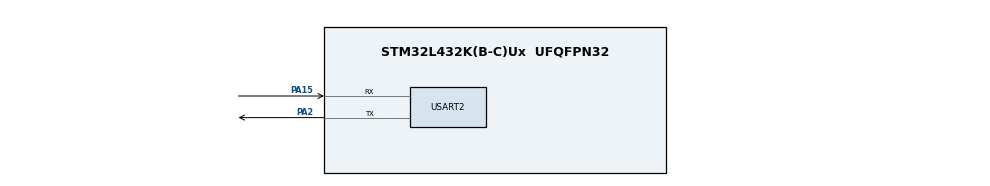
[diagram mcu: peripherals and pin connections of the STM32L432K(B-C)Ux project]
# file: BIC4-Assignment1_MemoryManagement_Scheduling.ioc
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FREERTOS.Tasks01=fibonacciTask,24,128,startFibonacciTask,Default,NULL,Dynamic,NULL,NULL;outputTask,24,128,startOutputTask,Default,NULL,Dynamic,NULL,NULL;devideTask,24,128,startDevideTask,Default,NULL,Dynamic,NULL,NULL;printBinaryTask,24,128,startPrintBinaryTask,Default,NULL,Dynamic,NULL,NULL
FREERTOS.configUSE_NEWLIB_REENTRANT=1
FREERTOS.configUSE_PREEMPTION=1
Mcu.Family=STM32L4
Mcu.Name=STM32L432K(B-C)Ux
Mcu.Package=UFQFPN32
NVIC.PriorityGroup=NVIC_PRIORITYGROUP_4
NVIC.TIM6_DAC_IRQn=true\:15\:0\:false\:false\:true\:false\:false\:true
NVIC.TimeBase=TIM6_DAC_IRQn
NVIC.TimeBaseIP=TIM6
NVIC.USART2_IRQn=true\:5\:0\:false\:false\:true\:true\:true\:true
PA13\ (JTMS-SWDIO).Mode=Serial_Wire
PA13\ (JTMS-SWDIO).Signal=SYS_JTMS-SWDIO
PA14\ (JTCK-SWCLK).Mode=Serial_Wire
PA14\ (JTCK-SWCLK).Signal=SYS_JTCK-SWCLK
PA15\ (JTDI).Mode=Asynchronous
PA15\ (JTDI).Signal=USART2_RX
PA2.Mode=Asynchronous
PA2.Signal=USART2_TX
ProjectManager.HeapSize=0x200
ProjectManager.StackSize=0x400
ProjectManager.TargetToolchain=STM32CubeIDE
RCC.HSE_VALUE=8000000
RCC.HSI48_VALUE=48000000
RCC.HSI_VALUE=16000000
RCC.LSE_VALUE=32768
RCC.MSI_VALUE=4000000
RCC.VCOOutputFreq_Value=32000000
USART2.VirtualMode-Asynchronous=VM_ASYNC
VP_FREERTOS_VS_CMSIS_V2.Mode=CMSIS_V2
VP_SYS_VS_tim6.Mode=TIM6
board=custom

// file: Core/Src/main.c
/* USER CODE BEGIN Header */
/**
  ******************************************************************************
  * @file           : main.c
  * @brief          : Main program body
  ******************************************************************************
  * @attention
  *
  * <h2><center>&copy; Copyright (c) 2022 STMicroelectronics.
  * All rights reserved.</center></h2>
  *
  * This software component is licensed by ST under BSD 3-Clause license,
  * the "License"; You may not use this file except in compliance with the
  * License. You may obtain a copy of the License at:
  *                        opensource.org/licenses/BSD-3-Clause
  *
  ******************************************************************************
  */
/* USER CODE END Header */
#include "main.h"
#include "cmsis_os.h"

/* USER CODE BEGIN Includes */
#include <stdlib.h>
#include <stdio.h>
/* USER CODE END Includes */

UART_HandleTypeDef huart2;

/* Definitions for fibonacciTask */
osThreadId_t fibonacciTaskHandle;
const osThreadAttr_t fibonacciTask_attributes = {
  .name = "fibonacciTask",
  .stack_size = 128 * 4,
  .priority = (osPriority_t) osPriorityNormal,
};
/* Definitions for outputTask */
osThreadId_t outputTaskHandle;
const osThreadAttr_t outputTask_attributes = {
  .name = "outputTask",
  .stack_size = 128 * 4,
  .priority = (osPriority_t) osPriorityNormal,
};
/* Definitions for devideTask */
osThreadId_t devideTaskHandle;
const osThreadAttr_t devideTask_attributes = {
  .name = "devideTask",
  .stack_size = 128 * 4,
  .priority = (osPriority_t) osPriorityNormal,
};
/* Definitions for printBinaryTask */
osThreadId_t printBinaryTaskHandle;
const osThreadAttr_t printBinaryTask_attributes = {
  .name = "printBinaryTask",
  .stack_size = 128 * 4,
  .priority = (osPriority_t) osPriorityNormal,
};

void SystemClock_Config(void);
static void MX_GPIO_Init(void);
static void MX_USART2_UART_Init(void);
void startFibonacciTask(void *argument);
void startOutputTask(void *argument);
void startDevideTask(void *argument);
void startPrintBinaryTask(void *argument);

/* USER CODE BEGIN 0 */

/**
  * @brief Fibonacci-Zahl berechnen
  * @param Index der Fibonacci-Folge
  * @retval Fibonacci-Zahl des Indexes
  */
int fibonacci(int zahl) {

	/* Die Fibonacci-Zahl von null ist null */
    if (zahl == 0) {
        return 0;
    }

    /* Die Fibonacci-Zahl von eins ist eins */
    if (zahl == 1) {
        return 1;
    }

    /* Ansonsten wird die Summe der zwei vorherigen Fibonacci-Zahlen zurückgegeben. */
    return fibonacci(zahl - 1) + fibonacci(zahl - 2);
}

/**
  * @brief Rest einer Zahl berechnen
  * @param Dividend
  * @param Devisor
  * @retval Ergebnis
  */
int divide(int x, int y) {

   if(x >= y)
	   return (1 + divide(x - y, y));
   if(x)
	   // printf("Zahl nicht teilbar -> Rest: %d -> ", x);
   return 0;
}

/**
  * @brief Dezimalzahl in Binärdarstellung darstellen
  * @param Dezimalzahl
  * @retval none
  */
void printBinary(long x) {
    if (x<2)
    {
    	// printf("%d",x);
    }
    else
    {
    	printBinary(x/2);
    	// printf("%d",x%2);
    }
}

/**
  * @brief Ausgabe am UART definieren
  * @param Zeichen zur Ausgabe am UART
  * @retval Zeichen
  */
int __io_putchar(int ch)
{
	int ret;

	while( (ret = HAL_UART_GetState(&huart2)) != HAL_UART_STATE_READY );

	if(ch == '\n')
	{
		static unsigned char buf[2]={'\r','\n'};
		HAL_UART_Transmit_IT(&huart2, buf, 2);
	}
	else
	{
		static unsigned char buf;
		buf= (unsigned char) ch;
		HAL_UART_Transmit_IT(&huart2, &buf, 1);
	}

	return ch;
}

/* USER CODE END 0 */

int main(void)
{

  /* MCU Configuration--------------------------------------------------------*/

  /* Reset of all peripherals, Initializes the Flash interface and the Systick. */
  HAL_Init();

  /* Configure the system clock */
  SystemClock_Config();

  /* Initialize all configured peripherals */
  MX_GPIO_Init();
  MX_USART2_UART_Init();

  /* Init scheduler */
  osKernelInitialize();

  /* Create the thread(s) */
  /* creation of fibonacciTask */
  fibonacciTaskHandle = osThreadNew(startFibonacciTask, NULL, &fibonacciTask_attributes);

  /* creation of outputTask */
  outputTaskHandle = osThreadNew(startOutputTask, NULL, &outputTask_attributes);

  /* creation of devideTask */
  devideTaskHandle = osThreadNew(startDevideTask, NULL, &devideTask_attributes);

  /* creation of printBinaryTask */
  printBinaryTaskHandle = osThreadNew(startPrintBinaryTask, NULL, &printBinaryTask_attributes);

  /* Start scheduler */
  osKernelStart();

  /* We should never get here as control is now taken by the scheduler */
  /* Infinite loop */
  while (1)
  {

  }
}

void SystemClock_Config(void)
{
  RCC_OscInitTypeDef RCC_OscInitStruct = {0};
  RCC_ClkInitTypeDef RCC_ClkInitStruct = {0};

  /** Configure the main internal regulator output voltage
  */
  if (HAL_PWREx_ControlVoltageScaling(PWR_REGULATOR_VOLTAGE_SCALE1) != HAL_OK)
  {
    Error_Handler();
  }
  /** Initializes the RCC Oscillators according to the specified parameters
  * in the RCC_OscInitTypeDef structure.
  */
  RCC_OscInitStruct.OscillatorType = RCC_OSCILLATORTYPE_MSI;
  RCC_OscInitStruct.MSIState = RCC_MSI_ON;
  RCC_OscInitStruct.MSICalibrationValue = 0;
  RCC_OscInitStruct.MSIClockRange = RCC_MSIRANGE_6;
  RCC_OscInitStruct.PLL.PLLState = RCC_PLL_NONE;
  if (HAL_RCC_OscConfig(&RCC_OscInitStruct) != HAL_OK)
  {
    Error_Handler();
  }
  /** Initializes the CPU, AHB and APB buses clocks
  */
  RCC_ClkInitStruct.ClockType = RCC_CLOCKTYPE_HCLK|RCC_CLOCKTYPE_SYSCLK
                              |RCC_CLOCKTYPE_PCLK1|RCC_CLOCKTYPE_PCLK2;
  RCC_ClkInitStruct.SYSCLKSource = RCC_SYSCLKSOURCE_MSI;
  RCC_ClkInitStruct.AHBCLKDivider = RCC_SYSCLK_DIV1;
  RCC_ClkInitStruct.APB1CLKDivider = RCC_HCLK_DIV1;
  RCC_ClkInitStruct.APB2CLKDivider = RCC_HCLK_DIV1;

  if (HAL_RCC_ClockConfig(&RCC_ClkInitStruct, FLASH_LATENCY_0) != HAL_OK)
  {
    Error_Handler();
  }
}

static void MX_USART2_UART_Init(void)
{

  huart2.Instance = USART2;
  huart2.Init.BaudRate = 115200;
  huart2.Init.WordLength = UART_WORDLENGTH_8B;
  huart2.Init.StopBits = UART_STOPBITS_1;
  huart2.Init.Parity = UART_PARITY_NONE;
  huart2.Init.Mode = UART_MODE_TX_RX;
  huart2.Init.HwFlowCtl = UART_HWCONTROL_NONE;
  huart2.Init.OverSampling = UART_OVERSAMPLING_16;
  huart2.Init.OneBitSampling = UART_ONE_BIT_SAMPLE_DISABLE;
  huart2.AdvancedInit.AdvFeatureInit = UART_ADVFEATURE_NO_INIT;
  if (HAL_UART_Init(&huart2) != HAL_OK)
  {
    Error_Handler();
  }

}

static void MX_GPIO_Init(void)
{

  /* GPIO Ports Clock Enable */
  __HAL_RCC_GPIOA_CLK_ENABLE();

}

void startFibonacciTask(void *argument)
{
  /* USER CODE BEGIN 5 */
  /* Infinite loop */
  for(;;)
  {
	  /* Zahl, welche sich bei jedem Durchlauf erhöht */
	  static int zahl = 0;

	  /* wenn Zahl = 20, Zahl auf 0 setzen */
	  if(zahl==20){
		  zahl=0;
	  }

	  /* Fibonacci-Zahl des Indexes(Zahl) ermitteln */
	  int erg =fibonacci(zahl);

	  /* Fibonacci-Zahl des Inexes(Zahl) ausgeben  */
	  // printf("Die Fibonacci-Zahl von(%d) lautet: %d\n", zahl, erg);

	  zahl++;
	  osDelay(2000);
  }
  /* USER CODE END 5 */
}

void startOutputTask(void *argument)
{
  /* USER CODE BEGIN startOutputTask */
  /* Infinite loop */
  for(;;)
  {
	  /* Ausgabe des Gesamt-Stack-Size und den verbleibenden Stack-Size der 3 Tasks (FibonacciTask,DevideTask und PrintBinaryTask) */
	  printf("FibonacciTask: stackSize= %d remaining= %d | DevideTask: stackSize= %d remaining= %d | PrintBinaryTask: stackSize= %d remaining= %d\n",fibonacciTask_attributes.stack_size,osThreadGetStackSpace(fibonacciTaskHandle),     devideTask_attributes.stack_size,osThreadGetStackSpace(devideTaskHandle),  printBinaryTask_attributes.stack_size,osThreadGetStackSpace(printBinaryTaskHandle));
	  osDelay(1000);
  }
  osThreadTerminate(outputTaskHandle);
  /* USER CODE END startOutputTask */
}

void startDevideTask(void *argument)
{
  /* USER CODE BEGIN startDevideTask */
  /* Infinite loop */
  for(;;)
  {

	  /* Zahl, welche sich bei jedem Durchlauf erhöht */
	  static int zahl = 0;

	  /* wenn Zahl = 80, Zahl auf 0 setzen */
	  if(zahl==80)
	  {
		  zahl=0;
	  }

	  /* Rest der Zahl berechnen */
	  int erg = divide(zahl, 3);

	  /* Ausgabe des Restes des Zufallszahl */
	  // printf("%d/3 = Ergebnis : %d\n",zahl, divide(zahl, 3));

	  zahl+=4;
	  osDelay(2000);
  }

  osThreadTerminate(devideTaskHandle);
  /* USER CODE END startDevideTask */
}

void startPrintBinaryTask(void *argument)
{
  /* USER CODE BEGIN startPrintBinaryTask */
  /* Infinite loop */
  for(;;)
  {
	  /* Zahl, welche sich bei jedem Durchlauf erhöht */
	  static long zahl = 0;

	  /* wenn Zahl = 1000000000, Zahl auf 0 setzen */
	  if(zahl == 1000000000)
	  {
		  zahl=0;
	  }

	  /* Zahl in Binärdarstellung umrechnen */
	  printBinary(zahl);

	  zahl+=1000;
	  osDelay(70);
  }

  osThreadTerminate(printBinaryTaskHandle);
  /* USER CODE END startPrintBinaryTask */
}

void HAL_TIM_PeriodElapsedCallback(TIM_HandleTypeDef *htim)
{
  if (htim->Instance == TIM6) {
    HAL_IncTick();
  }
}

void Error_Handler(void)
{
  __disable_irq();
  while (1)
  {
  }
}

/************************ (C) COPYRIGHT STMicroelectronics *****END OF FILE****/
